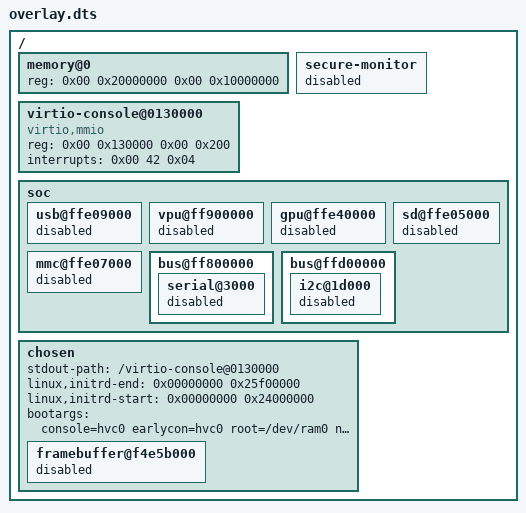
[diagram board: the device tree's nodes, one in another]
/*
 * Copyright 2024, UNSW
 *
 * SPDX-License-Identifier: BSD-2-Clause
 */

/ {
    /delete-node/ memory@0;
    /delete-node/ chosen;

    memory@0 {
		device_type = "memory";
		reg = <0x00 0x20000000 0x00 0x10000000>;
	};

    secure-monitor {
		status = "disabled";
	};

	virtio-console@0130000 {
		compatible = "virtio,mmio";
		reg = <0x00 0x130000 0x00 0x200>;
		interrupts = <0x00 42 0x04>;
	};

    soc {
        usb@ffe09000 {
            status = "disabled";
        };

        vpu@ff900000 {
            status = "disabled";
        };

        gpu@ffe40000 {
            status = "disabled";
        };

        sd@ffe05000 {
            status = "disabled";
        };

        mmc@ffe07000 {
            status = "disabled";
        };

		bus@ff800000 {
			serial@3000 {
                status = "disabled";
            };
        };

		bus@ffd00000 {
			i2c@1d000 {
                status = "disabled";
            };
        };
    };

	chosen {
		#address-cells = <0x02>;
		#size-cells = <0x02>;
		ranges;
        stdout-path = "/virtio-console@0130000";
		linux,initrd-end = <0x00000000 0x25f00000>;
        linux,initrd-start = <0x00000000 0x24000000>;
        bootargs = "console=hvc0 earlycon=hvc0 root=/dev/ram0 nosmp rw loglevel=8 pci=nomsi earlyprintk=serial maxcpus=1";
		// root=/dev/nfs nfsroot=/vmm-rfs
		// root=/dev/mmcblk0p1 rootwait

		framebuffer@f4e5b000 {
			status = "disabled";
		};
	};
};
